# ATSAMC21N18A register map
Registers are 32-bit, access not given, no defined reset value unless marked. A register's access mark holds for its fields unless they carry their own. Addresses are absolute; registers are grouped by the start of their names; [hi:lo] are bit positions; 'fields as' and 'values as' point back to an identical list.

## SERCOM1
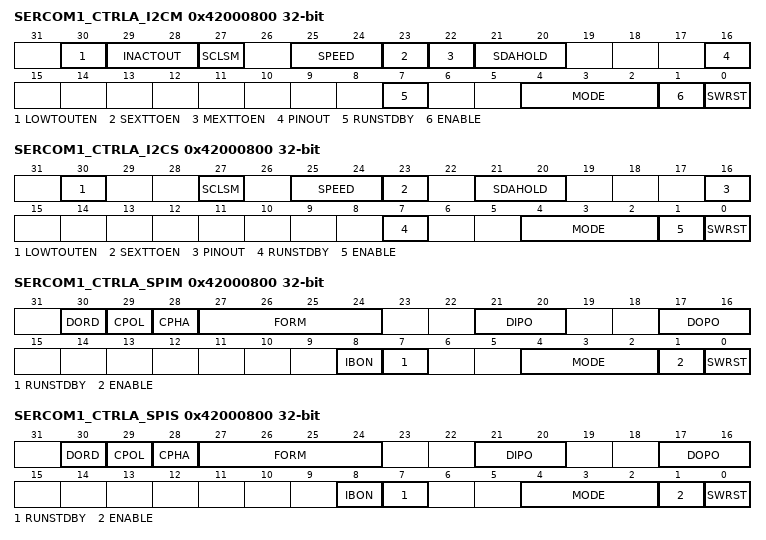
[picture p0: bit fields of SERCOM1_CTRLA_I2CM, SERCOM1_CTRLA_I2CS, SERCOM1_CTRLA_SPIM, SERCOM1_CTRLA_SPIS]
0x42000800 SERCOM1_CTRLA_I2CM — I2CM Control A
  [30] LOWTOUTEN — SCL Low Timeout Enable
  [29:28] INACTOUT — Inactive Time-Out
  [27] SCLSM — SCL Clock Stretch Mode
  [25:24] SPEED — Transfer Speed
  [23] SEXTTOEN — Slave SCL Low Extend Timeout
  [22] MEXTTOEN — Master SCL Low Extend Timeout
  [21:20] SDAHOLD — SDA Hold Time
  [16] PINOUT — Pin Usage
  [7] RUNSTDBY — Run in Standby
  [4:2] MODE — Operating Mode
  [1] ENABLE
  [0] SWRST — Software Reset
0x42000800 SERCOM1_CTRLA_I2CS — I2CS Control A
  [30] LOWTOUTEN — SCL Low Timeout Enable
  [27] SCLSM — SCL Clock Stretch Mode
  [25:24] SPEED — Transfer Speed
  [23] SEXTTOEN — Slave SCL Low Extend Timeout
  [21:20] SDAHOLD — SDA Hold Time
  [16] PINOUT — Pin Usage
  [7] RUNSTDBY — Run during Standby
  [4:2] MODE — Operating Mode
  [1] ENABLE
  [0] SWRST — Software Reset
0x42000800 SERCOM1_CTRLA_SPIM — SPIM Control A
  [30] DORD — Data Order
  [29] CPOL — Clock Polarity
  [28] CPHA — Clock Phase
  [27:24] FORM — Frame Format
  [21:20] DIPO — Data In Pinout
  [17:16] DOPO — Data Out Pinout
  [8] IBON — Immediate Buffer Overflow Notification
  [7] RUNSTDBY — Run during Standby
  [4:2] MODE — Operating Mode
  [1] ENABLE
  [0] SWRST — Software Reset
0x42000800 SERCOM1_CTRLA_SPIS — SPIS Control A
  fields as SERCOM1_CTRLA_SPIM
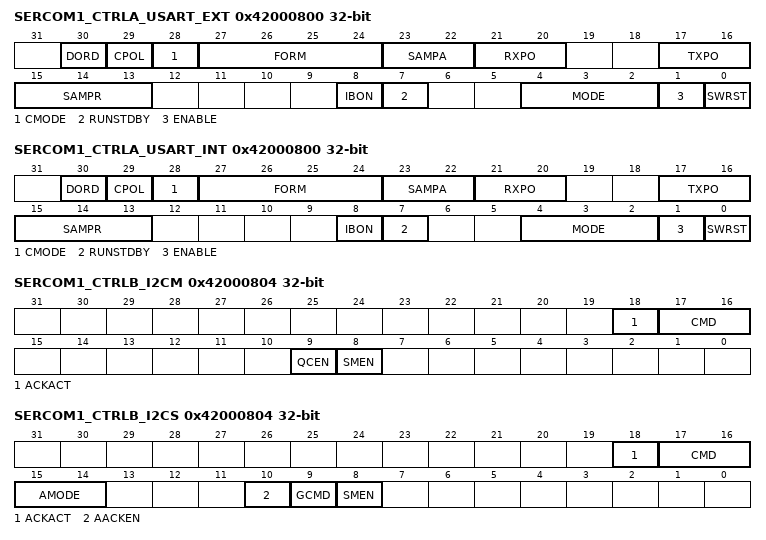
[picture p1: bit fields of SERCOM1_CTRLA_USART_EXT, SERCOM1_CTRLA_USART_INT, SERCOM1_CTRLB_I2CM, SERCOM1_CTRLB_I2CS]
0x42000800 SERCOM1_CTRLA_USART_EXT — USART_EXT Control A
  [30] DORD — Data Order
  [29] CPOL — Clock Polarity
  [28] CMODE — Communication Mode
  [27:24] FORM — Frame Format
  [23:22] SAMPA — Sample Adjustment
  [21:20] RXPO — Receive Data Pinout
  [17:16] TXPO — Transmit Data Pinout
  [15:13] SAMPR — Sample
  [8] IBON — Immediate Buffer Overflow Notification
  [7] RUNSTDBY — Run during Standby
  [4:2] MODE — Operating Mode
  [1] ENABLE
  [0] SWRST — Software Reset
0x42000800 SERCOM1_CTRLA_USART_INT — USART_INT Control A
  fields as SERCOM1_CTRLA_USART_EXT
0x42000804 SERCOM1_CTRLB_I2CM — I2CM Control B
  [18] ACKACT — Acknowledge Action
  [17:16] CMD — Command
  [9] QCEN — Quick Command Enable
  [8] SMEN — Smart Mode Enable
0x42000804 SERCOM1_CTRLB_I2CS — I2CS Control B
  [18] ACKACT — Acknowledge Action
  [17:16] CMD — Command
  [15:14] AMODE — Address Mode
  [10] AACKEN — Automatic Address Acknowledge
  [9] GCMD — PMBus Group Command
  [8] SMEN — Smart Mode Enable
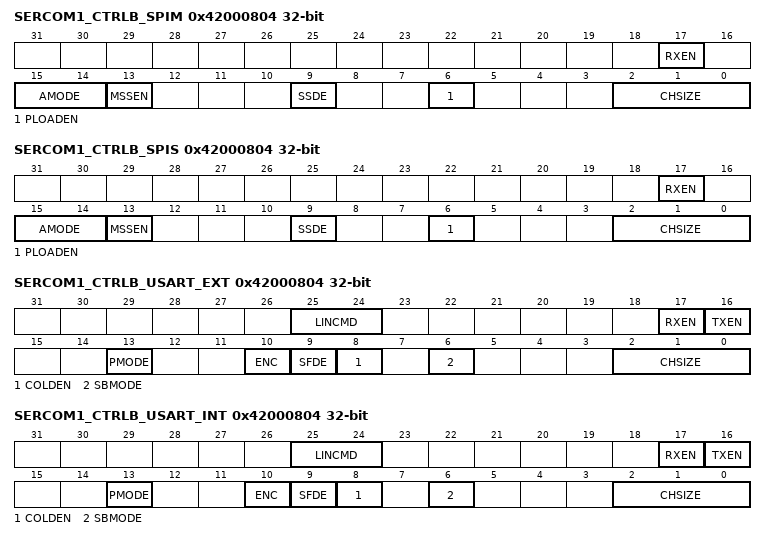
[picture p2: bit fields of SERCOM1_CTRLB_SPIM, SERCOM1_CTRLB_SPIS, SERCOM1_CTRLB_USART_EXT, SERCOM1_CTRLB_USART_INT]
0x42000804 SERCOM1_CTRLB_SPIM — SPIM Control B
  [17] RXEN — Receiver Enable
  [15:14] AMODE — Address Mode
  [13] MSSEN — Master Slave Select Enable
  [9] SSDE — Slave Select Low Detect Enable
  [6] PLOADEN — Data Preload Enable
  [2:0] CHSIZE — Character Size
0x42000804 SERCOM1_CTRLB_SPIS — SPIS Control B
  fields as SERCOM1_CTRLB_SPIM
0x42000804 SERCOM1_CTRLB_USART_EXT — USART_EXT Control B
  [25:24] LINCMD — LIN Command
  [17] RXEN — Receiver Enable
  [16] TXEN — Transmitter Enable
  [13] PMODE — Parity Mode
  [10] ENC — Encoding Format
  [9] SFDE — Start of Frame Detection Enable
  [8] COLDEN — Collision Detection Enable
  [6] SBMODE — Stop Bit Mode
  [2:0] CHSIZE — Character Size
0x42000804 SERCOM1_CTRLB_USART_INT — USART_INT Control B
  fields as SERCOM1_CTRLB_USART_EXT
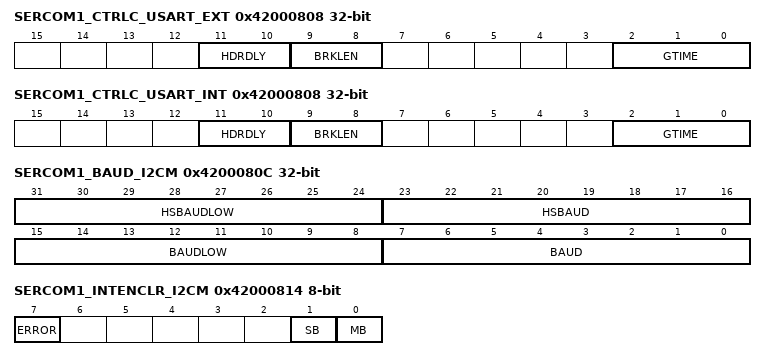
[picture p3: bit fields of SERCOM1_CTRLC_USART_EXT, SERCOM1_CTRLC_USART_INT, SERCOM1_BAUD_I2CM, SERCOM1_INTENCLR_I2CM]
0x42000808 SERCOM1_CTRLC_USART_EXT — USART_EXT Control C
  [11:10] HDRDLY — LIN Master Header Delay
  [9:8] BRKLEN — LIN Master Break Length
  [2:0] GTIME — RS485 Guard Time
0x42000808 SERCOM1_CTRLC_USART_INT — USART_INT Control C
  fields as SERCOM1_CTRLC_USART_EXT
0x4200080C SERCOM1_BAUD_I2CM — I2CM Baud Rate
  [31:24] HSBAUDLOW — High Speed Baud Rate Value Low
  [23:16] HSBAUD — High Speed Baud Rate Value
  [15:8] BAUDLOW — Baud Rate Value Low
  [7:0] BAUD — Baud Rate Value
0x4200080C SERCOM1_BAUD_SPIM 8-bit — SPIM Baud Rate
  [7:0] BAUD — Baud Rate Value
0x4200080C SERCOM1_BAUD_SPIS 8-bit — SPIS Baud Rate
  [7:0] BAUD — Baud Rate Value
0x4200080C SERCOM1_BAUD_USART_EXT 16-bit — USART_EXT Baud Rate
  [15:13] FP — Fractional Part
  [12:0] BAUD — Baud Rate Value
  [15:0] BAUD — Baud Rate Value
0x4200080C SERCOM1_BAUD_USART_INT 16-bit — USART_INT Baud Rate
  fields as SERCOM1_BAUD_USART_EXT
0x4200080E SERCOM1_RXPL_USART_EXT 8-bit — USART_EXT Receive Pulse Length
  [7:0] RXPL — Receive Pulse Length
0x4200080E SERCOM1_RXPL_USART_INT 8-bit — USART_INT Receive Pulse Length
  [7:0] RXPL — Receive Pulse Length
0x42000814 SERCOM1_INTENCLR_I2CM 8-bit — I2CM Interrupt Enable Clear
  [7] ERROR — Combined Error Interrupt Disable
  [1] SB — Slave On Bus Interrupt Disable
  [0] MB — Master On Bus Interrupt Disable
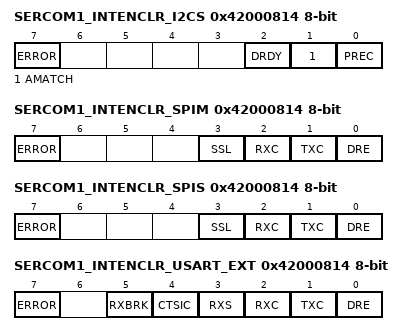
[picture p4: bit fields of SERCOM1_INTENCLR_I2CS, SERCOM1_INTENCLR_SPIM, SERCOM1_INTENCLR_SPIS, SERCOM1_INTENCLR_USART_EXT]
0x42000814 SERCOM1_INTENCLR_I2CS 8-bit — I2CS Interrupt Enable Clear
  [7] ERROR — Combined Error Interrupt Disable
  [2] DRDY — Data Interrupt Disable
  [1] AMATCH — Address Match Interrupt Disable
  [0] PREC — Stop Received Interrupt Disable
0x42000814 SERCOM1_INTENCLR_SPIM 8-bit — SPIM Interrupt Enable Clear
  [7] ERROR — Combined Error Interrupt Disable
  [3] SSL — Slave Select Low Interrupt Disable
  [2] RXC — Receive Complete Interrupt Disable
  [1] TXC — Transmit Complete Interrupt Disable
  [0] DRE — Data Register Empty Interrupt Disable
0x42000814 SERCOM1_INTENCLR_SPIS 8-bit — SPIS Interrupt Enable Clear
  fields as SERCOM1_INTENCLR_SPIM
0x42000814 SERCOM1_INTENCLR_USART_EXT 8-bit — USART_EXT Interrupt Enable Clear
  [7] ERROR — Combined Error Interrupt Disable
  [5] RXBRK — Break Received Interrupt Disable
  [4] CTSIC — Clear To Send Input Change Interrupt Disable
  [3] RXS — Receive Start Interrupt Disable
  [2] RXC — Receive Complete Interrupt Disable
  [1] TXC — Transmit Complete Interrupt Disable
  [0] DRE — Data Register Empty Interrupt Disable
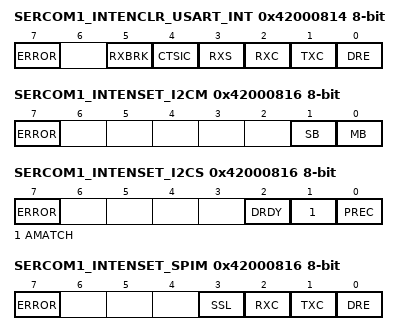
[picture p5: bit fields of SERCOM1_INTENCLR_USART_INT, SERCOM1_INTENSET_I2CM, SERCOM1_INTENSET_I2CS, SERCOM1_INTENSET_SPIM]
0x42000814 SERCOM1_INTENCLR_USART_INT 8-bit — USART_INT Interrupt Enable Clear
  fields as SERCOM1_INTENCLR_USART_EXT
0x42000816 SERCOM1_INTENSET_I2CM 8-bit — I2CM Interrupt Enable Set
  [7] ERROR — Combined Error Interrupt Enable
  [1] SB — Slave On Bus Interrupt Enable
  [0] MB — Master On Bus Interrupt Enable
0x42000816 SERCOM1_INTENSET_I2CS 8-bit — I2CS Interrupt Enable Set
  [7] ERROR — Combined Error Interrupt Enable
  [2] DRDY — Data Interrupt Enable
  [1] AMATCH — Address Match Interrupt Enable
  [0] PREC — Stop Received Interrupt Enable
0x42000816 SERCOM1_INTENSET_SPIM 8-bit — SPIM Interrupt Enable Set
  [7] ERROR — Combined Error Interrupt Enable
  [3] SSL — Slave Select Low Interrupt Enable
  [2] RXC — Receive Complete Interrupt Enable
  [1] TXC — Transmit Complete Interrupt Enable
  [0] DRE — Data Register Empty Interrupt Enable
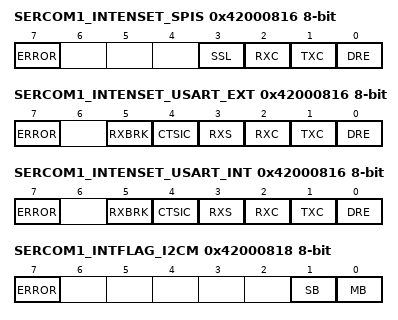
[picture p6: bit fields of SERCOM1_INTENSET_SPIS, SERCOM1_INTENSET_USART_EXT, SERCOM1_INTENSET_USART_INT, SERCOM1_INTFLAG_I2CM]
0x42000816 SERCOM1_INTENSET_SPIS 8-bit — SPIS Interrupt Enable Set
  fields as SERCOM1_INTENSET_SPIM
0x42000816 SERCOM1_INTENSET_USART_EXT 8-bit — USART_EXT Interrupt Enable Set
  [7] ERROR — Combined Error Interrupt Enable
  [5] RXBRK — Break Received Interrupt Enable
  [4] CTSIC — Clear To Send Input Change Interrupt Enable
  [3] RXS — Receive Start Interrupt Enable
  [2] RXC — Receive Complete Interrupt Enable
  [1] TXC — Transmit Complete Interrupt Enable
  [0] DRE — Data Register Empty Interrupt Enable
0x42000816 SERCOM1_INTENSET_USART_INT 8-bit — USART_INT Interrupt Enable Set
  fields as SERCOM1_INTENSET_USART_EXT
0x42000818 SERCOM1_INTFLAG_I2CM 8-bit — I2CM Interrupt Flag Status and Clear
  [7] ERROR — Combined Error Interrupt
  [1] SB — Slave On Bus Interrupt
  [0] MB — Master On Bus Interrupt
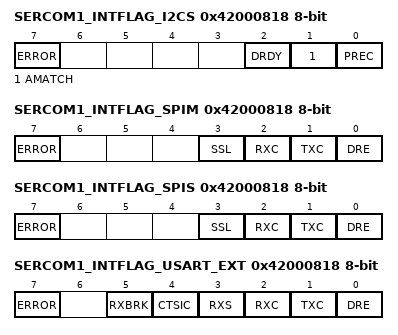
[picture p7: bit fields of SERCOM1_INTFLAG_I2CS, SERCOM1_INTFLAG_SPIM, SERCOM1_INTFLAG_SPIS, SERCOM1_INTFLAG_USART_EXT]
0x42000818 SERCOM1_INTFLAG_I2CS 8-bit — I2CS Interrupt Flag Status and Clear
  [7] ERROR — Combined Error Interrupt
  [2] DRDY — Data Interrupt
  [1] AMATCH — Address Match Interrupt
  [0] PREC — Stop Received Interrupt
0x42000818 SERCOM1_INTFLAG_SPIM 8-bit — SPIM Interrupt Flag Status and Clear
  [7] ERROR — Combined Error Interrupt
  [3] SSL — Slave Select Low Interrupt Flag
  [2] RXC — Receive Complete Interrupt
  [1] TXC — Transmit Complete Interrupt
  [0] DRE — Data Register Empty Interrupt
0x42000818 SERCOM1_INTFLAG_SPIS 8-bit — SPIS Interrupt Flag Status and Clear
  fields as SERCOM1_INTFLAG_SPIM
0x42000818 SERCOM1_INTFLAG_USART_EXT 8-bit — USART_EXT Interrupt Flag Status and Clear
  [7] ERROR — Combined Error Interrupt
  [5] RXBRK — Break Received Interrupt
  [4] CTSIC — Clear To Send Input Change Interrupt
  [3] RXS — Receive Start Interrupt
  [2] RXC — Receive Complete Interrupt
  [1] TXC — Transmit Complete Interrupt
  [0] DRE — Data Register Empty Interrupt
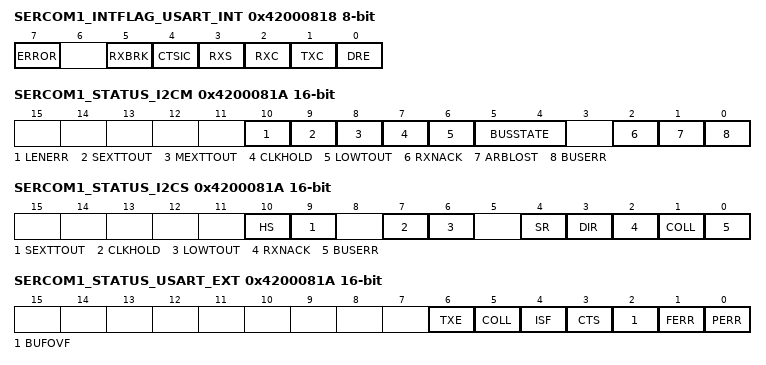
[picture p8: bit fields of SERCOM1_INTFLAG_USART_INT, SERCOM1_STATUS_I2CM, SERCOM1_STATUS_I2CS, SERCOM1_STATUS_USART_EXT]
0x42000818 SERCOM1_INTFLAG_USART_INT 8-bit — USART_INT Interrupt Flag Status and Clear
  fields as SERCOM1_INTFLAG_USART_EXT
0x4200081A SERCOM1_STATUS_I2CM 16-bit — I2CM Status
  [10] LENERR — Length Error
  [9] SEXTTOUT — Slave SCL Low Extend Timeout
  [8] MEXTTOUT — Master SCL Low Extend Timeout
  [7] CLKHOLD — Clock Hold
  [6] LOWTOUT — SCL Low Timeout
  [5:4] BUSSTATE
  [2] RXNACK — Received Not Acknowledge
  [1] ARBLOST — Arbitration Lost
  [0] BUSERR — Bus Error
0x4200081A SERCOM1_STATUS_I2CS 16-bit — I2CS Status
  [10] HS — High Speed
  [9] SEXTTOUT — Slave SCL Low Extend Timeout
  [7] CLKHOLD — Clock Hold
  [6] LOWTOUT — SCL Low Timeout
  [4] SR — Repeated Start
  [3] DIR — Read/Write Direction
  [2] RXNACK — Received Not Acknowledge
  [1] COLL — Transmit Collision
  [0] BUSERR — Bus Error
0x4200081A SERCOM1_STATUS_SPIM 16-bit — SPIM Status
  [2] BUFOVF — Buffer Overflow
0x4200081A SERCOM1_STATUS_SPIS 16-bit — SPIS Status
  [2] BUFOVF — Buffer Overflow
0x4200081A SERCOM1_STATUS_USART_EXT 16-bit — USART_EXT Status
  [6] TXE — Transmitter Empty
  [5] COLL — Collision Detected
  [4] ISF — Inconsistent Sync Field
  [3] CTS — Clear To Send
  [2] BUFOVF — Buffer Overflow
  [1] FERR — Frame Error
  [0] PERR — Parity Error
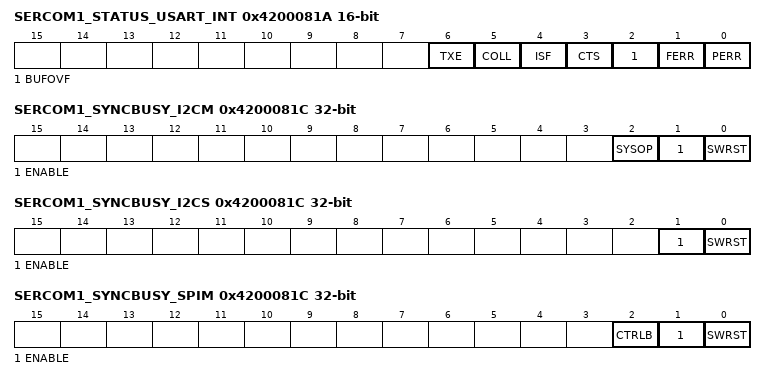
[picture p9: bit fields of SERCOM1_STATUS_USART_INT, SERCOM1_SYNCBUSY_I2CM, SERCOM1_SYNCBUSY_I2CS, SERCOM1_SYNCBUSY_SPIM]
0x4200081A SERCOM1_STATUS_USART_INT 16-bit — USART_INT Status
  fields as SERCOM1_STATUS_USART_EXT
0x4200081C SERCOM1_SYNCBUSY_I2CM — I2CM Synchronization Busy
  [2] SYSOP — System Operation Synchronization Busy
  [1] ENABLE — SERCOM Enable Synchronization Busy
  [0] SWRST — Software Reset Synchronization Busy
0x4200081C SERCOM1_SYNCBUSY_I2CS — I2CS Synchronization Busy
  [1] ENABLE — SERCOM Enable Synchronization Busy
  [0] SWRST — Software Reset Synchronization Busy
0x4200081C SERCOM1_SYNCBUSY_SPIM — SPIM Synchronization Busy
  [2] CTRLB — CTRLB Synchronization Busy
  [1] ENABLE — SERCOM Enable Synchronization Busy
  [0] SWRST — Software Reset Synchronization Busy
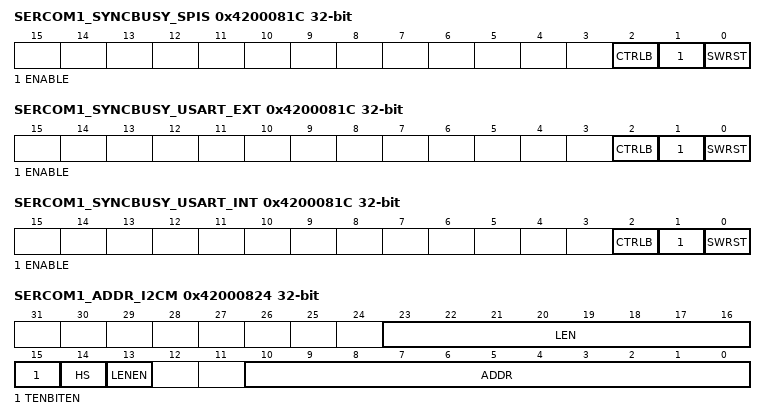
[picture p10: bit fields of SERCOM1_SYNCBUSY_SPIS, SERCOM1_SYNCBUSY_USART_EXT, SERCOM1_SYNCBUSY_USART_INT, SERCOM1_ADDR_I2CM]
0x4200081C SERCOM1_SYNCBUSY_SPIS — SPIS Synchronization Busy
  fields as SERCOM1_SYNCBUSY_SPIM
0x4200081C SERCOM1_SYNCBUSY_USART_EXT — USART_EXT Synchronization Busy
  fields as SERCOM1_SYNCBUSY_SPIM
0x4200081C SERCOM1_SYNCBUSY_USART_INT — USART_INT Synchronization Busy
  fields as SERCOM1_SYNCBUSY_SPIM
0x42000824 SERCOM1_ADDR_I2CM — I2CM Address
  [23:16] LEN — Length
  [15] TENBITEN — Ten Bit Addressing Enable
  [14] HS — High Speed Mode
  [13] LENEN — Length Enable
  [10:0] ADDR — Address Value
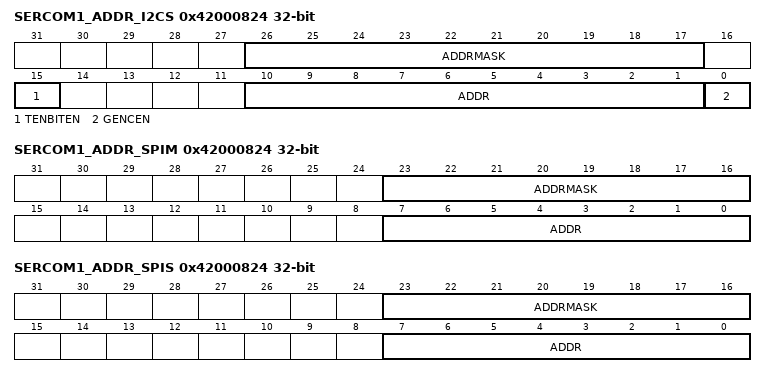
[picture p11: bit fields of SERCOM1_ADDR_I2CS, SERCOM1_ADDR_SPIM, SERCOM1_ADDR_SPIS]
0x42000824 SERCOM1_ADDR_I2CS — I2CS Address
  [26:17] ADDRMASK — Address Mask
  [15] TENBITEN — Ten Bit Addressing Enable
  [10:1] ADDR — Address Value
  [0] GENCEN — General Call Address Enable
0x42000824 SERCOM1_ADDR_SPIM — SPIM Address
  [23:16] ADDRMASK — Address Mask
  [7:0] ADDR — Address Value
0x42000824 SERCOM1_ADDR_SPIS — SPIS Address
  [23:16] ADDRMASK — Address Mask
  [7:0] ADDR — Address Value
0x42000828 SERCOM1_DATA_I2CM 8-bit — I2CM Data
  [7:0] DATA — Data Value
0x42000828 SERCOM1_DATA_I2CS 8-bit — I2CS Data
  [7:0] DATA — Data Value
0x42000828 SERCOM1_DATA_SPIM — SPIM Data
  [8:0] DATA — Data Value
0x42000828 SERCOM1_DATA_SPIS — SPIS Data
  [8:0] DATA — Data Value
0x42000828 SERCOM1_DATA_USART_EXT 16-bit — USART_EXT Data
  [8:0] DATA — Data Value
0x42000828 SERCOM1_DATA_USART_INT 16-bit — USART_INT Data
  [8:0] DATA — Data Value
0x42000830 SERCOM1_DBGCTRL_I2CM 8-bit — I2CM Debug Control
  [0] DBGSTOP — Debug Mode
0x42000830 SERCOM1_DBGCTRL_SPIM 8-bit — SPIM Debug Control
  [0] DBGSTOP — Debug Mode
0x42000830 SERCOM1_DBGCTRL_SPIS 8-bit — SPIS Debug Control
  [0] DBGSTOP — Debug Mode
0x42000830 SERCOM1_DBGCTRL_USART_EXT 8-bit — USART_EXT Debug Control
  [0] DBGSTOP — Debug Mode
0x42000830 SERCOM1_DBGCTRL_USART_INT 8-bit — USART_INT Debug Control
  [0] DBGSTOP — Debug Mode
